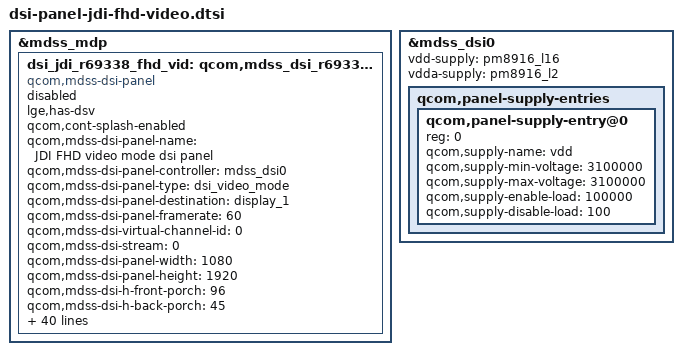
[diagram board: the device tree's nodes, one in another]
&mdss_mdp {
    dsi_jdi_r69338_fhd_vid: qcom,mdss_dsi_r69338_1080p_video{
            lge,has-dsv;
            compatible = "qcom,mdss-dsi-panel";
            status = "disable";
            qcom,cont-splash-enabled;
            qcom,mdss-dsi-panel-name = "JDI FHD video mode dsi panel";
            qcom,mdss-dsi-panel-controller = <&mdss_dsi0>;
            qcom,mdss-dsi-panel-type = "dsi_video_mode";
            qcom,mdss-dsi-panel-destination = "display_1";
            qcom,mdss-dsi-panel-framerate = <60>;
            qcom,mdss-dsi-virtual-channel-id = <0>;
            qcom,mdss-dsi-stream = <0>;
            qcom,mdss-dsi-panel-width = <1080>;
            qcom,mdss-dsi-panel-height = <1920>;
            qcom,mdss-dsi-h-front-porch = <96>;
            qcom,mdss-dsi-h-back-porch = <45>;
            qcom,mdss-dsi-h-pulse-width = <4>;
            qcom,mdss-dsi-h-sync-skew = <0>;
            qcom,mdss-dsi-v-back-porch = <4>;
            qcom,mdss-dsi-v-front-porch = <6>;
            qcom,mdss-dsi-v-pulse-width = <1>;
            qcom,mdss-dsi-h-left-border = <0>;
            qcom,mdss-dsi-h-right-border = <0>;
            qcom,mdss-dsi-v-top-border = <0>;
            qcom,mdss-dsi-v-bottom-border = <0>;
            qcom,mdss-pan-physical-width-dimension = <58>;
            qcom,mdss-pan-physical-height-dimension = <104>;
            qcom,mdss-dsi-bpp = <24>;
            qcom,mdss-dsi-color-order = "rgb_swap_rgb";
            qcom,mdss-dsi-underflow-color = <0x0>;
            //qcom,mdss-dsi-lp11-init = <1>;    //need to check
            qcom,mdss-dsi-border-color = <0>;
            qcom,mdss-dsi-on-command = [
				39 01 00 00 00 00 02
				51 ff
				
				39 01 00 00 00 00 02
				53 0c
				
				39 01 00 00 00 00 02
				55 00
				
				29 01 00 00 00 00 02
				b0 04
				
				29 01 00 00 00 00 14
				c8 01 00 00 fa 00 fc
				00 00 00 fa 00 fc 00
				00 00 00 00 fc 00
				
				29 01 00 00 00 00 07
				b8 07 90 1e 10 1e 32
				
				29 01 00 00 00 00 07
				b9 07 82 3c 10 3c 87
				
				29 01 00 00 00 00 07
				ba 07 78 64 10 64 b4
				
				29 01 00 00 00 00 19
				ce 75 40 43 49 55 62
				71 82 94 a8 b9 cb db
				e9 f5 fc ff 07 25 04
				04 44 00 00
				
				29 01 00 00 00 00 04
				bb 01 1e 14
				
				29 01 00 00 00 00 04
				bc 01 50 32
				
				29 01 00 00 00 00 04
				bd 01 b4 a0
				
				29 01 00 00 00 00 21
				ca 00 80 80 80 80 80
				80 80 08 20 80 80 0a
				4a 37 a0 55 f8 0c 0c
				20 10 3f 3f 00 00 10
				10 3f 3f 3f 3f

				29 01 00 00 00 00 02
				b0 04

				29 01 00 00 00 00 05
				b1 84 60 00 01
				
				29 01 00 00 00 00 02
				d6 01
				
				05 01 00 00 00 00 03
				11
				
				05 01 00 00 00 00 03
				29				

            ];

            qcom,mdss-dsi-off-command = [
                05 01 00 00 14 00 01
                28
                05 01 00 00 50 00 01
                10
            ];

            qcom,mdss-dsi-on-command-state = "dsi_lp_mode";
            qcom,mdss-dsi-off-command-state = "dsi_hs_mode";
            qcom,mdss-dsi-h-sync-pulse = <0>;
            qcom,mdss-dsi-traffic-mode = "non_burst_sync_event";
            qcom,mdss-dsi-lane-map = "lane_map_0123";
            qcom,mdss-dsi-bllp-eof-power-mode;
            qcom,mdss-dsi-bllp-power-mode;
            qcom,mdss-dsi-lane-0-state;
            qcom,mdss-dsi-lane-1-state;
            qcom,mdss-dsi-lane-2-state;
            qcom,mdss-dsi-lane-3-state;

			qcom,mdss-dsi-panel-timings = [E2 36 24 00 66 68 28 38 2A 03 04 00];
            qcom,mdss-dsi-t-clk-post = <0x02>;
            qcom,mdss-dsi-t-clk-pre = <0x2A>;
            qcom,mdss-dsi-bl-min-level = <1>;
            qcom,mdss-dsi-bl-max-level = <255>;
            qcom,mdss-dsi-dma-trigger = "trigger_sw";
            qcom,mdss-dsi-mdp-trigger = "none";
            //qcom,mdss-dsi-bl-pmic-control-type = "bl_ctrl_wled";
            qcom,mdss-dsi-reset-sequence = <1 10>;
        };
};
&mdss_dsi0 {
    vdd-supply = <&pm8916_l16>;
    vdda-supply = <&pm8916_l2>;
    qcom,panel-supply-entries {
        qcom,panel-supply-entry@0 {
            reg = <0>;
            qcom,supply-name = "vdd";
            qcom,supply-min-voltage = <3100000>;
            qcom,supply-max-voltage = <3100000>;
            qcom,supply-enable-load = <100000>;
            qcom,supply-disable-load = <100>;
        };
    };
};

